# SIM3L164_C register map
File version: 1
CPU: 
Registers are 32-bit, read-write, reset 0x0 unless marked. A register's access mark holds for its fields unless they carry their own. Offsets are from the block's base; [hi:lo] are bit positions.

## DTM_0
Base 0x4004A000
Same registers: DTM_1 0x4004B000, DTM_2 0x4004C000
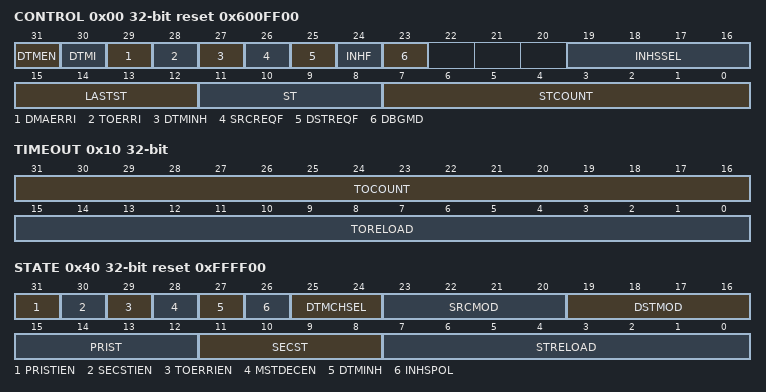
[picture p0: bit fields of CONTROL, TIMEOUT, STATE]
0x00 CONTROL reset 0x600FF00 — Module Control
  [31] DTMEN — Module Enable.
    0=DISABLED (Disable the DTM module.); 1=ENABLED (Enable the DTM module.)
  [30] DTMI — Module Interrupt Flag.
    0=NOT_SET (A state transition or timeout has not occurred.); 1=SET (A state transition (SECSTIEN or PRISTIEN set to 1) or timeout (TOERRIEN = 1) occurred.)
  [29] DMAERRI — DMA Error Interrupt Flag.
    0=NOT_SET (A DMA error has not occurred.); 1=SET (A DMA error occurred.)
  [28] TOERRI — Timeout Error Interrupt Flag.
    0=NOT_SET (A timeout error has not occurred.); 1=SET (A timeout error occurred.)
  [27] DTMINH — DTM Module Inhibit.
    0=INACTIVE (The DTM module does not ignore DMA requests.); 1=ACTIVE (The DTM module ignores DMA requests until this bit is cleared.)
  [26] SRCREQF ro — Source Peripheral DMA Request Status Flag.
    0=NOT_SET (The source peripheral did not request a DMA transfer.); 1=SET (The source peripheral requested a DMA transfer.)
  [25] DSTREQF ro — Destination Peripheral DMA Request Status Flag.
    0=NOT_SET (The destination peripheral did not request a DMA transfer.); 1=SET (The destination peripheral requested a DMA transfer.)
  [24] INHF ro — Inhibit Status Flag.
    0=NOT_SET (The inhibit signal is inactive.); 1=SET (The inhibit signal is active.)
  [23] DBGMD — Debug Mode.
    0=RUN (The DTM module will continue to operate while the core is halted in debug mode.); 1=HALT (A debug breakpoint will cause the DTM module to halt.)
  [19:16] INHSSEL — Inhibit Signal Select.
    0=DTMNINH0 (Select inhibit signal source DTMnINH.0.); 1=DTMNINH1 (Select inhibit signal source DTMnINH.1.); 2=DTMNINH2 (Select inhibit signal source DTMnINH.2.); 3=DTMNINH3 (Select inhibit signal source DTMnINH.3.); 4=DTMNINH4 (Select inhibit signal source DTMnINH.4.); 5=DTMNINH5 (Select inhibit signal source DTMnINH.5.); 6=DTMNINH6 (Select inhibit signal source DTMnINH.6.); 7=DTMNINH7 (Select inhibit signal source DTMnINH.7.); 8=DTMNINH8 (Select inhibit signal source DTMnINH.8.); 9=DTMNINH9 (Select inhibit signal source DTMnINH.9.); 10=DTMNINH10 (Select inhibit signal source DTMnINH.10.); 11=DTMNINH11 (Select inhibit signal source DTMnINH.11.); 12=DTMNINH12 (Select inhibit signal source DTMnINH.12.); 13=DTMNINH13 (Select inhibit signal source DTMnINH.13.); 14=DTMNINH14 (Select inhibit signal source DTMnINH.14.); 15=DTMNINH15 (Select inhibit signal source DTMnINH.15.)
  [15:12] LASTST ro — Last State.
  [11:8] ST — Active State.
  [7:0] STCOUNT — Active State Counter.
0x10 TIMEOUT — Module Timeout
  [31:16] TOCOUNT — Timeout Counter.
  [15:0] TORELOAD — Timeout Counter Reload.
0x20 MSTCOUNT — Master Counter
  [15:0] MSTCOUNT — Master Counter.
0x30 STATEADDR — State Address
  [31:2] STATEADDR — State Address.
0x40 STATE reset 0xFFFF00 — Active DTM State
  [31] PRISTIEN ro — Primary State Transition Interrupt Enable.
    0=DISABLED (Disable primary state transition interrupts.); 1=ENABLED (Enable primary state transition interrupts.)
  [30] SECSTIEN ro — Secondary State Transition Interrupt Enable.
    0=DISABLED (Disable secondary state transition interrupts.); 1=ENABLED (Enable secondary state transition interrupts.)
  [29] TOERRIEN ro — Timeout Enable.
    0=DISABLED (Disable timeouts and timeout interrupts.); 1=ENABLED (Enable timeouts and timeout interrupts.)
  [28] MSTDECEN ro — Master Decrement Enable.
    0=DISABLED (Disable master counter decrements.); 1=ENABLED (Enable master counter decrements.)
  [27] DTMINH ro — Module Inhibit Enable.
    0=INACTIVE (The DTM module does not ignore any DMA requests.); 1=ACTIVE (The DTM module ignores all DMA requests until the inhibit signal selected by INHSSEL matches the polarity polarity set by INHSPOL.)
  [26] INHSPOL ro — Inhibit Signal Polarity.
    0=ACTIVE_LOW (A logic low on the pin selected by INHSEL will allow the DTM to proceed.); 1=ACTIVE_HIGH (A logic high on the pin selected by INHSEL will allow the DTM to proceed.)
  [25:24] DTMCHSEL ro — DTM Channel Select.
    0=CH_A (Select DTMn channel A for this state.); 1=CH_B (Select DTMn channel B for this state.); 2=CH_C (Select DTMn channel C for this state.); 3=CH_D (Select DTMn channel D for this state.)
  [23:20] SRCMOD ro — Source Module.
    0=DTMNSRC0 (Select source module DTMnSRC.0.); 1=DTMNSRC1 (Select source module DTMnSRC.1.); 2=DTMNSRC2 (Select source module DTMnSRC.2.); 3=DTMNSRC3 (Select source module DTMnSRC.3.); 4=DTMNSRC4 (Select source module DTMnSRC.4.); 5=DTMNSRC5 (Select source module DTMnSRC.5.); 6=DTMNSRC6 (Select source module DTMnSRC.6.); 7=DTMNSRC7 (Select source module DTMnSRC.7.); 8=DTMNSRC8 (Select source module DTMnSRC.8.); 9=DTMNSRC9 (Select source module DTMnSRC.9.); 10=DTMNSRC10 (Select source module DTMnSRC.10.); 11=DTMNSRC11 (Select source module DTMnSRC.11.); 12=DTMNSRC12 (Select source module DTMnSRC.12.); 13=DTMNSRC13 (Select source module DTMnSRC.13.); 14=DTMNSRC14 (Select source module DTMnSRC.14.); 15=DTMNSRC15 (Select no source module (DTMnSRC.15).)
  [19:16] DSTMOD ro — Destination Module.
    0=DTMNDST0 (Select destination module DTMnDST.0.); 1=DTMNDST1 (Select destination module DTMnDST.1.); 2=DTMNDST2 (Select destination module DTMnDST.2.); 3=DTMNDST3 (Select destination module DTMnDST.3.); 4=DTMNDST4 (Select destination module DTMnDST.4.); 5=DTMNDST5 (Select destination module DTMnDST.5.); 6=DTMNDST6 (Select destination module DTMnDST.6.); 7=DTMNDST7 (Select destination module DTMnDST.7.); 8=DTMNDST8 (Select destination module DTMnDST.8.); 9=DTMNDST9 (Select destination module DTMnDST.9.); 10=DTMNDST10 (Select destination module DTMnDST.10.); 11=DTMNDST11 (Select destination module DTMnDST.11.); 12=DTMNDST12 (Select destination module DTMnDST.12.); 13=DTMNDST13 (Select destination module DTMnDST.13.); 14=DTMNDST14 (Select destination module DTMnDST.14.); 15=DTMNDST15 (Select no destination module (DTMnDST.15).)
  [15:12] PRIST ro — Primary State.
  [11:8] SECST ro — Secondary State.
  [7:0] STRELOAD ro — Active State Counter Reload.
